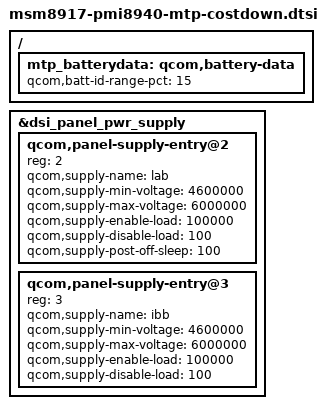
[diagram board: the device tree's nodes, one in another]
/*
 * Copyright (c) 2017, The Linux Foundation. All rights reserved.
 *
 * This program is free software; you can redistribute it and/or modify
 * it under the terms of the GNU General Public License version 2 and
 * only version 2 as published by the Free Software Foundation.
 *
 * This program is distributed in the hope that it will be useful,
 * but WITHOUT ANY WARRANTY; without even the implied warranty of
 * MERCHANTABILITY or FITNESS FOR A PARTICULAR PURPOSE.  See the
 * GNU General Public License for more details.
 */

//#include "msm-pmi8940-costdown.dtsi"
#include "msm8917-mtp-costdown.dtsi"
#include "components/memmap/memmap_8917_v0.dtsi"

/*&soc {
	led_flash0: qcom,camera-flash {
		cell-index = <0>;
		compatible = "qcom,camera-flash";
		qcom,flash-type = <1>;
		qcom,flash-source = <&pmi8940_flash0 &pmi8940_flash1>;
		qcom,torch-source = <&pmi8940_torch0 &pmi8940_torch1>;
		qcom,switch-source = <&pmi8940_switch>;
	};
};*/

// ADD start charging hangxing.jiang 2018.01.03
/{
	mtp_batterydata: qcom,battery-data {
		qcom,batt-id-range-pct = <15>;
	// MOD start new_batterdata hangxing.jiang 2018.01.16
		#include "batterydata_HE338cos_4100mah.dtsi"
	// MOD end new_batterdata hangxing.jiang 2018.01.16
	// Modify begin by ext-hangxing.jiang for: new_batterydata
		#include "batterydata_HE341lishen_4000mAh.dtsi"
	// Modify end
	};
};

/*
&pmi8940_fg {
	qcom,battery-data = <&mtp_batterydata>;
};
// ADD end charging hangxing.jiang 2018.01.03

&mdss_dsi0 {
	lab-supply = <&lab_regulator>;
	ibb-supply = <&ibb_regulator>;
};

&labibb {
	status = "ok";
	qpnp,qpnp-labibb-mode = "lcd";
};

&ibb_regulator {
	qcom,qpnp-ibb-discharge-resistor = <32>;
};
*/

&dsi_panel_pwr_supply {
	qcom,panel-supply-entry@2 {
		reg = <2>;
		qcom,supply-name = "lab";
		qcom,supply-min-voltage = <4600000>;
		qcom,supply-max-voltage = <6000000>;
		qcom,supply-enable-load = <100000>;
		qcom,supply-disable-load = <100>;
		qcom,supply-post-off-sleep = <100>;
	};

	qcom,panel-supply-entry@3 {
		reg = <3>;
		qcom,supply-name = "ibb";
		qcom,supply-min-voltage = <4600000>;
		qcom,supply-max-voltage = <6000000>;
		qcom,supply-enable-load = <100000>;
		qcom,supply-disable-load = <100>;
	};
};
